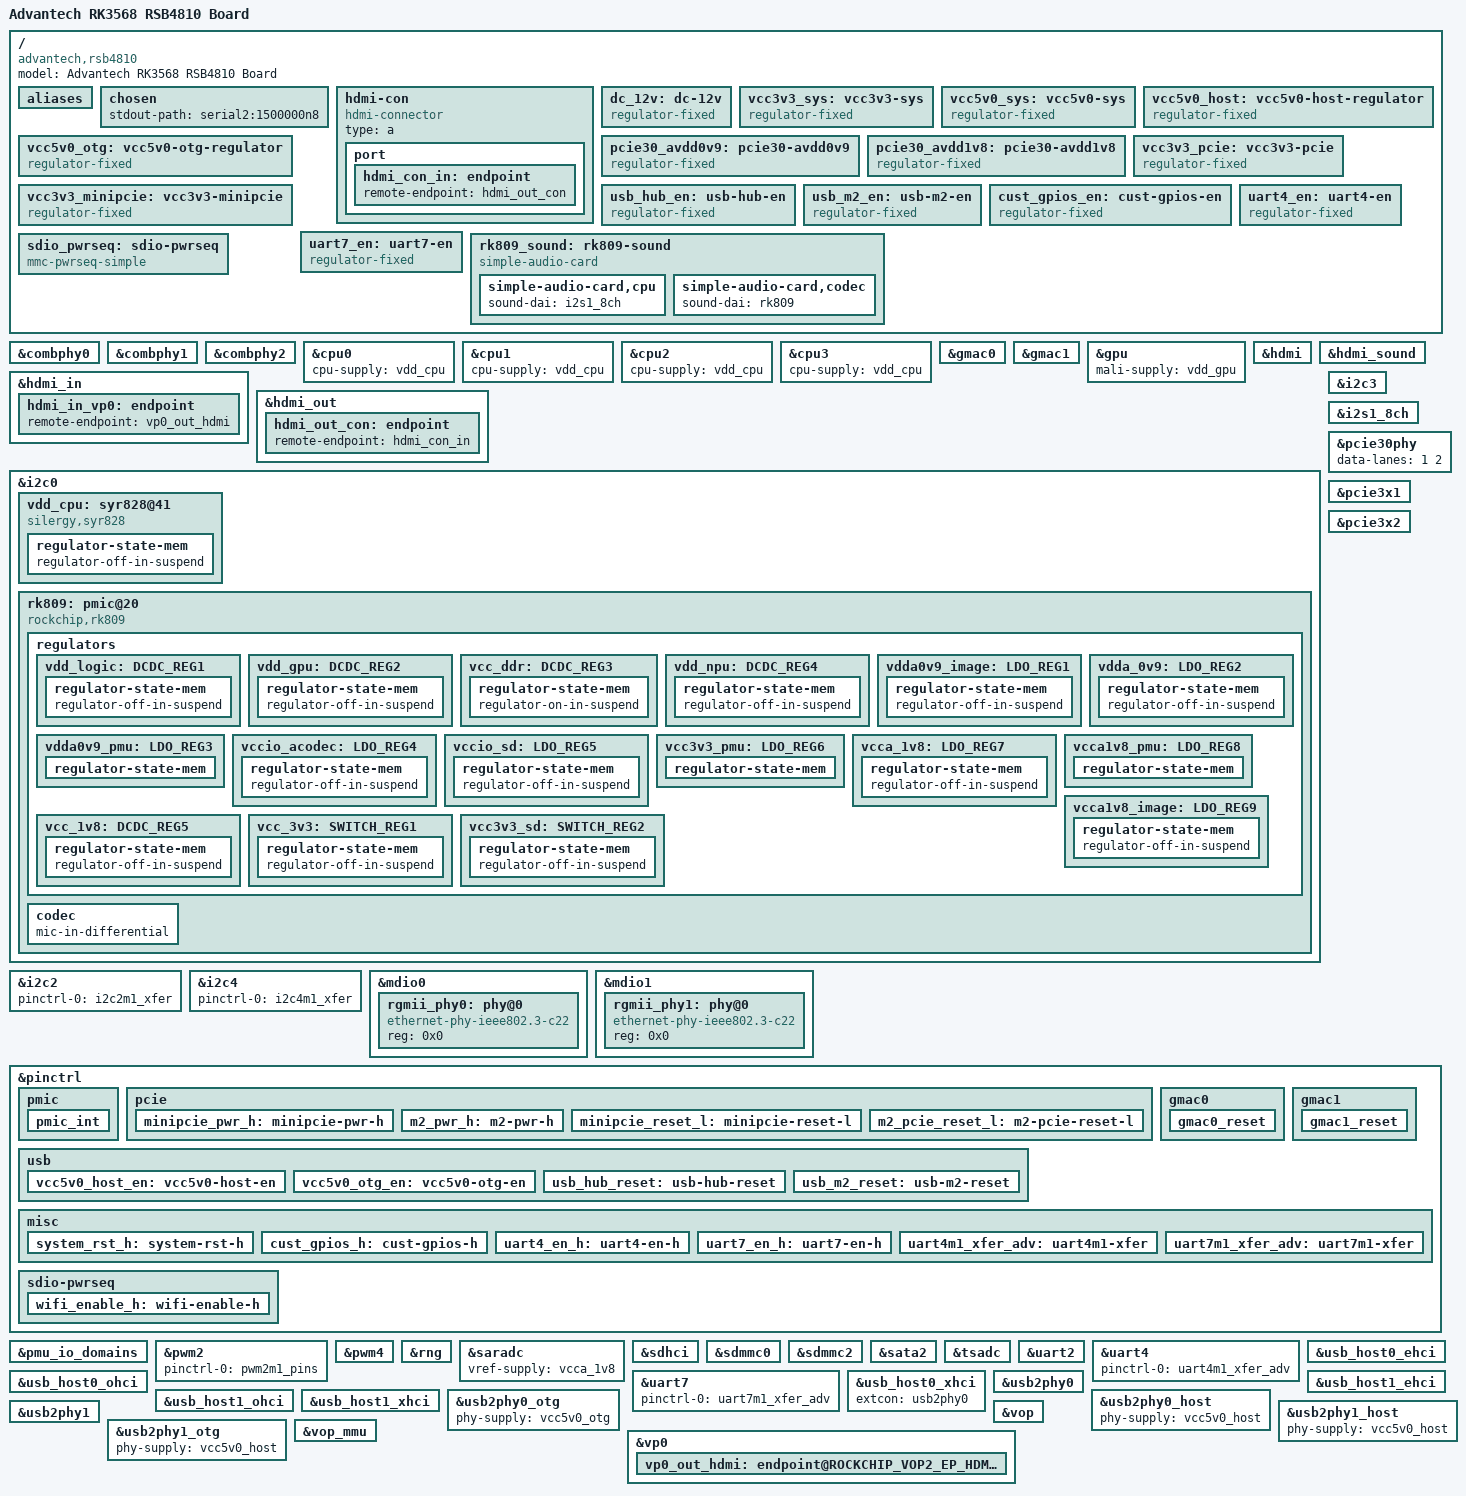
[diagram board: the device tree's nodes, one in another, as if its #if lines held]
// SPDX-License-Identifier: (GPL-2.0+ OR MIT)

/dts-v1/;
#include <dt-bindings/gpio/gpio.h>
#include <dt-bindings/pinctrl/rockchip.h>
#include <dt-bindings/soc/rockchip,vop2.h>
#include "rk3568.dtsi"

/ {
	model = "Advantech RK3568 RSB4810 Board";
	compatible = "advantech,rsb4810", "rockchip,rk3568";

	aliases {
		ethernet0 = &gmac0;
		ethernet1 = &gmac1;
		mmc0 = &sdhci;
		mmc1 = &sdmmc0;
	};

	chosen: chosen {
		stdout-path = "serial2:1500000n8";
	};

#ifdef DTS_NO_LEGACY
	hdmi-con {
		compatible = "hdmi-connector";
		type = "a";

		port {
			hdmi_con_in: endpoint {
				remote-endpoint = <&hdmi_out_con>;
			};
		};
	};
#endif

	dc_12v: dc-12v {
		compatible = "regulator-fixed";
		regulator-name = "dc_12v";
		regulator-always-on;
		regulator-boot-on;
		regulator-min-microvolt = <12000000>;
		regulator-max-microvolt = <12000000>;
	};

	vcc3v3_sys: vcc3v3-sys {
		compatible = "regulator-fixed";
		regulator-name = "vcc3v3_sys";
		regulator-always-on;
		regulator-boot-on;
		regulator-min-microvolt = <3300000>;
		regulator-max-microvolt = <3300000>;
		vin-supply = <&dc_12v>;
	};

	vcc5v0_sys: vcc5v0-sys {
		compatible = "regulator-fixed";
		regulator-name = "vcc5v0_sys";
		regulator-always-on;
		regulator-boot-on;
		regulator-min-microvolt = <5000000>;
		regulator-max-microvolt = <5000000>;
		vin-supply = <&dc_12v>;
	};

	vcc5v0_host: vcc5v0-host-regulator {
		compatible = "regulator-fixed";
		enable-active-high;
		gpio = <&gpio0 RK_PA6 GPIO_ACTIVE_HIGH>;
		pinctrl-names = "default";
		pinctrl-0 = <&vcc5v0_host_en>;
		regulator-name = "vcc5v0_host";
		regulator-min-microvolt = <5000000>;
		regulator-max-microvolt = <5000000>;
	};

	vcc5v0_otg: vcc5v0-otg-regulator {
		compatible = "regulator-fixed";
		enable-active-high;
		gpio = <&gpio0 RK_PA5 GPIO_ACTIVE_HIGH>;
		pinctrl-names = "default";
		pinctrl-0 = <&vcc5v0_otg_en>;
		regulator-name = "vcc5v0_otg";
		regulator-min-microvolt = <5000000>;
		regulator-max-microvolt = <5000000>;
	};

	pcie30_avdd0v9: pcie30-avdd0v9 {
		compatible = "regulator-fixed";
		regulator-name = "pcie30_avdd0v9";
		regulator-always-on;
		regulator-boot-on;
		regulator-min-microvolt = <900000>;
		regulator-max-microvolt = <900000>;
		vin-supply = <&vcc3v3_sys>;
	};

	pcie30_avdd1v8: pcie30-avdd1v8 {
		compatible = "regulator-fixed";
		regulator-name = "pcie30_avdd1v8";
		regulator-always-on;
		regulator-boot-on;
		regulator-min-microvolt = <1800000>;
		regulator-max-microvolt = <1800000>;
		vin-supply = <&vcc3v3_sys>;
	};

	vcc3v3_pcie: vcc3v3-pcie {
		compatible = "regulator-fixed";
		enable-active-high;
		gpios = <&gpio0 RK_PC6 GPIO_ACTIVE_HIGH>;
		pinctrl-0 = <&m2_pwr_h>;
		pinctrl-names = "default";
		regulator-name = "vcc3v3_pcie";
		regulator-min-microvolt = <3300000>;
		regulator-max-microvolt = <3300000>;
	};

	vcc3v3_minipcie: vcc3v3-minipcie {
		compatible = "regulator-fixed";
		enable-active-high;
		gpios = <&gpio0 RK_PD4 GPIO_ACTIVE_HIGH>;
		pinctrl-0 = <&minipcie_pwr_h>;
		pinctrl-names = "default";
		regulator-name = "vcc3v3_minipcie";
		regulator-min-microvolt = <3300000>;
		regulator-max-microvolt = <3300000>;
	};
	
	usb_hub_en: usb-hub-en {
		compatible = "regulator-fixed";
		enable-active-high;
		gpio = <&gpio0 RK_PB7 GPIO_ACTIVE_HIGH>;
		pinctrl-0 = <&usb_hub_reset>;
		pinctrl-names = "default";
		regulator-name = "usb_hub_en";
		regulator-always-on;
		regulator-boot-on;
	};

	usb_m2_en: usb-m2-en {
		compatible = "regulator-fixed";
		enable-active-high;
		gpio = <&gpio3 RK_PB5 GPIO_ACTIVE_HIGH>;
		pinctrl-0 = <&usb_m2_reset>;
		pinctrl-names = "default";
		regulator-name = "usb_m2_en";
		regulator-always-on;
		regulator-boot-on;
	};

	cust_gpios_en: cust-gpios-en {
		compatible = "regulator-fixed";
		enable-active-high;
		pinctrl-0 = <&cust_gpios_h>;
		pinctrl-names = "default";
		gpio = <&gpio2 RK_PD0 GPIO_ACTIVE_HIGH>;
		regulator-name = "cust_gpio_en";
		regulator-always-on;
		regulator-boot-on;
	};

	uart4_en: uart4-en {
		compatible = "regulator-fixed";
		enable-active-high;
		pinctrl-0 = <&uart4_en_h>;
		pinctrl-names = "default";
		gpio = <&gpio4 RK_PB2 GPIO_ACTIVE_HIGH>;
		regulator-name = "uart4_en";
		regulator-always-on;
		regulator-boot-on;
	};

	uart7_en: uart7-en {
		compatible = "regulator-fixed";
		enable-active-high;
		pinctrl-0 = <&uart7_en_h>;
		pinctrl-names = "default";
		gpio = <&gpio4 RK_PC0 GPIO_ACTIVE_HIGH>;
		regulator-name = "uart7_en";
		regulator-always-on;
		regulator-boot-on;
	};

	sdio_pwrseq: sdio-pwrseq {
		compatible = "mmc-pwrseq-simple";
		clocks = <&rk809 1>;
		clock-names = "ext_clock";
		pinctrl-0 = <&wifi_enable_h>;
		pinctrl-names = "default";

		/*
		 * On the module itself this is one of these (depending
		 * on the actual card populated):
		 * - SDIO_RESET_L_WL_REG_ON
		 * - PDN (power down when low)
		 */
		post-power-on-delay-ms = <200>;
		reset-gpios = <&gpio2 RK_PC6 GPIO_ACTIVE_LOW>;
	};

	rk809_sound: rk809-sound {
		compatible = "simple-audio-card";
		simple-audio-card,format = "i2s";
		simple-audio-card,name = "Analog RK809";
		simple-audio-card,mclk-fs = <256>;

		simple-audio-card,cpu {
			sound-dai = <&i2s1_8ch>;
		};
		simple-audio-card,codec {
			sound-dai = <&rk809>;
		};
	};
};

&combphy0 {
	status = "okay";
};

&combphy1 {
	status = "okay";
};

&combphy2 {
	status = "okay";
};

&cpu0 {
	cpu-supply = <&vdd_cpu>;
};

&cpu1 {
	cpu-supply = <&vdd_cpu>;
};

&cpu2 {
	cpu-supply = <&vdd_cpu>;
};

&cpu3 {
	cpu-supply = <&vdd_cpu>;
};

&gmac0 {
	assigned-clocks = <&cru SCLK_GMAC0_RX_TX>, <&cru SCLK_GMAC0>;
	assigned-clock-parents = <&cru SCLK_GMAC0_RGMII_SPEED>, <&cru CLK_MAC0_2TOP>;
	assigned-clock-rates = <0>, <125000000>;
	clock_in_out = "input";
	phy-mode = "rgmii";
	pinctrl-names = "default";
	pinctrl-0 = <&gmac0_reset
		     &gmac0_miim
		     &gmac0_tx_bus2
		     &gmac0_rx_bus2
		     &gmac0_rgmii_clk
		     &gmac0_rgmii_bus>;
	snps,reset-gpio = <&gpio3 RK_PB7 GPIO_ACTIVE_LOW>;
	snps,reset-active-low;
	/* Reset time is 20ms, 100ms for rtl8211f */
	snps,reset-delays-us = <0 20000 100000>;
	enable_phy_delay = <0>;
	tx_delay = <0x37>;
	rx_delay = <0x0d>;
	phy-handle = <&rgmii_phy0>;
	status = "okay";
};

&gmac1 {
	assigned-clocks = <&cru SCLK_GMAC1_RX_TX>, <&cru SCLK_GMAC1>;
	assigned-clock-parents = <&cru SCLK_GMAC1_RGMII_SPEED>, <&cru CLK_MAC1_2TOP>;
	assigned-clock-rates = <0>, <125000000>;
	clock_in_out = "input";
	phy-mode = "rgmii";
	pinctrl-names = "default";
	pinctrl-0 = <&gmac1_reset
		     &gmac1m1_miim
		     &gmac1m1_tx_bus2
		     &gmac1m1_rx_bus2
		     &gmac1m1_rgmii_clk
		     &gmac1m1_rgmii_bus
		     &gmac1m1_clkinout>;
	snps,reset-gpio = <&gpio3 RK_PB0 GPIO_ACTIVE_LOW>;
	snps,reset-active-low;
	/* Reset time is 20ms, 100ms for rtl8211f */
	snps,reset-delays-us = <0 20000 100000>;
	enable_phy_delay = <0>;
	tx_delay = <0x3c>;
	rx_delay = <0x2f>;
	phy-handle = <&rgmii_phy1>;
	status = "okay";
};

#ifdef DTS_NO_LEGACY
&gpu {
	mali-supply = <&vdd_gpu>;
	status = "okay";
};

&hdmi {
	status = "okay";
};

&hdmi_in {
	hdmi_in_vp0: endpoint {
		remote-endpoint = <&vp0_out_hdmi>;
	};
};

&hdmi_out {
	hdmi_out_con: endpoint {
		remote-endpoint = <&hdmi_con_in>;
	};
};

&hdmi_sound {
	status = "okay";
};
#endif

&i2c0 {
	status = "okay";

	vdd_cpu: syr828@41 {
		compatible = "silergy,syr828";
		reg = <0x41>;
		vin-supply = <&vcc5v0_sys>;
		regulator-compatible = "fan53555-reg";
		regulator-name = "vdd_cpu";
		regulator-min-microvolt = <800000>;
		regulator-max-microvolt = <1250000>;
		regulator-ramp-delay = <1000>;
		fcs,suspend-voltage-selector = <1>;
		regulator-always-on;
		regulator-boot-on;

		regulator-state-mem {
			regulator-off-in-suspend;
		};
	};

	rk809: pmic@20 {
		compatible = "rockchip,rk809";
		reg = <0x20>;
		interrupt-parent = <&gpio0>;
		interrupts = <RK_PA3 IRQ_TYPE_LEVEL_LOW>;
		assigned-clocks = <&cru I2S1_MCLKOUT_TX>;
		assigned-clock-parents = <&cru CLK_I2S1_8CH_TX>;
		#clock-cells = <1>;
		clock-names = "mclk";
		clocks = <&cru I2S1_MCLKOUT_TX>;
		pinctrl-names = "default";
		pinctrl-0 = <&pmic_int>, <&i2s1m0_mclk>;
		rockchip,system-power-controller;
		#sound-dai-cells = <0>;
		wakeup-source;

		vcc1-supply = <&vcc3v3_sys>;
		vcc2-supply = <&vcc3v3_sys>;
		vcc3-supply = <&vcc3v3_sys>;
		vcc4-supply = <&vcc3v3_sys>;
		vcc5-supply = <&vcc3v3_sys>;
		vcc6-supply = <&vcc3v3_sys>;
		vcc7-supply = <&vcc3v3_sys>;
		vcc8-supply = <&vcc3v3_sys>;
		vcc9-supply = <&vcc3v3_sys>;

		regulators {
			vdd_logic: DCDC_REG1 {
				regulator-always-on;
				regulator-boot-on;
				regulator-min-microvolt = <500000>;
				regulator-max-microvolt = <1350000>;
				regulator-init-microvolt = <900000>;
				regulator-ramp-delay = <6001>;
				regulator-initial-mode = <0x2>;
				regulator-name = "vdd_logic";

				regulator-state-mem {
					regulator-off-in-suspend;
				};
			};

			vdd_gpu: DCDC_REG2 {
				regulator-always-on;
				regulator-boot-on;
				regulator-min-microvolt = <500000>;
				regulator-max-microvolt = <1350000>;
				regulator-init-microvolt = <900000>;
				regulator-ramp-delay = <6001>;
				regulator-initial-mode = <0x2>;
				regulator-name = "vdd_gpu";

				regulator-state-mem {
					regulator-off-in-suspend;
				};
			};

			vcc_ddr: DCDC_REG3 {
				regulator-always-on;
				regulator-boot-on;
				regulator-initial-mode = <0x2>;
				regulator-name = "vcc_ddr";

				regulator-state-mem {
					regulator-on-in-suspend;
				};
			};

			vdd_npu: DCDC_REG4 {
				regulator-always-on;
				regulator-boot-on;
				regulator-min-microvolt = <500000>;
				regulator-max-microvolt = <1350000>;
				regulator-init-microvolt = <900000>;
				regulator-ramp-delay = <6001>;
				regulator-initial-mode = <0x2>;
				regulator-name = "vdd_npu";

				regulator-state-mem {
					regulator-off-in-suspend;
				};
			};

			vdda0v9_image: LDO_REG1 {
				regulator-boot-on;
				regulator-always-on;
				regulator-min-microvolt = <900000>;
				regulator-max-microvolt = <900000>;
				regulator-name = "vdda0v9_image";

				regulator-state-mem {
					regulator-off-in-suspend;
				};
			};

			vdda_0v9: LDO_REG2 {
				regulator-always-on;
				regulator-boot-on;
				regulator-min-microvolt = <900000>;
				regulator-max-microvolt = <900000>;
				regulator-name = "vdda_0v9";

				regulator-state-mem {
					regulator-off-in-suspend;
				};
			};

			vdda0v9_pmu: LDO_REG3 {
				regulator-always-on;
				regulator-boot-on;
				regulator-min-microvolt = <900000>;
				regulator-max-microvolt = <900000>;
				regulator-name = "vdda0v9_pmu";

				regulator-state-mem {
					regulator-on-in-suspend;
					regulator-suspend-microvolt = <900000>;
				};
			};

			vccio_acodec: LDO_REG4 {
				regulator-always-on;
				regulator-boot-on;
				regulator-min-microvolt = <3300000>;
				regulator-max-microvolt = <3300000>;
				regulator-name = "vccio_acodec";

				regulator-state-mem {
					regulator-off-in-suspend;
				};
			};

			vccio_sd: LDO_REG5 {
				regulator-always-on;
				regulator-boot-on;
				regulator-min-microvolt = <1800000>;
				regulator-max-microvolt = <3300000>;
				regulator-name = "vccio_sd";
				regulator-state-mem {
					regulator-off-in-suspend;
				};
			};

			vcc3v3_pmu: LDO_REG6 {
				regulator-always-on;
				regulator-boot-on;
				regulator-min-microvolt = <3300000>;
				regulator-max-microvolt = <3300000>;
				regulator-name = "vcc3v3_pmu";

				regulator-state-mem {
					regulator-on-in-suspend;
					regulator-suspend-microvolt = <3300000>;
				};
			};

			vcca_1v8: LDO_REG7 {
				regulator-always-on;
				regulator-boot-on;
				regulator-min-microvolt = <1800000>;
				regulator-max-microvolt = <1800000>;
				regulator-name = "vcca_1v8";

				regulator-state-mem {
					regulator-off-in-suspend;
				};
			};

			vcca1v8_pmu: LDO_REG8 {
				regulator-always-on;
				regulator-boot-on;
				regulator-min-microvolt = <1800000>;
				regulator-max-microvolt = <1800000>;
				regulator-name = "vcca1v8_pmu";

				regulator-state-mem {
					regulator-on-in-suspend;
					regulator-suspend-microvolt = <1800000>;
				};
			};

			vcca1v8_image: LDO_REG9 {
				regulator-always-on;
				regulator-boot-on;
				regulator-min-microvolt = <1800000>;
				regulator-max-microvolt = <1800000>;
				regulator-name = "vcca1v8_image";

				regulator-state-mem {
					regulator-off-in-suspend;
				};
			};

			vcc_1v8: DCDC_REG5 {
				regulator-always-on;
				regulator-boot-on;
				regulator-min-microvolt = <1800000>;
				regulator-max-microvolt = <1800000>;
				regulator-name = "vcc_1v8";

				regulator-state-mem {
					regulator-off-in-suspend;
				};
			};

			vcc_3v3: SWITCH_REG1 {
				regulator-always-on;
				regulator-boot-on;
				regulator-name = "vcc_3v3";

				regulator-state-mem {
					regulator-off-in-suspend;
				};
			};

			vcc3v3_sd: SWITCH_REG2 {
				regulator-always-on;
				regulator-boot-on;
				regulator-name = "vcc3v3_sd";

				regulator-state-mem {
					regulator-off-in-suspend;
				};
			};
		};

		codec {
			mic-in-differential;
		};
	};
};

&i2c2 {
	status = "okay";
	pinctrl-names = "default";
	pinctrl-0 = <&i2c2m1_xfer>;
};

&i2c3 {
	status = "okay";
};

&i2c4 {
	status = "okay";
	pinctrl-names = "default";
	pinctrl-0 = <&i2c4m1_xfer>;
};

&i2s1_8ch {
	status = "okay";
	rockchip,trcm-sync-tx-only;
	pinctrl-names = "default";
	pinctrl-0 = <&i2s1m0_sclktx
		     &i2s1m0_lrcktx
		     &i2s1m0_sdi0
		     &i2s1m0_sdo0>;
};

&mdio0 {
	rgmii_phy0: phy@0 {
		compatible = "ethernet-phy-ieee802.3-c22";
		reg = <0x0>;
	};
};

&mdio1 {
	rgmii_phy1: phy@0 {
		compatible = "ethernet-phy-ieee802.3-c22";
		reg = <0x0>;
	};
};

&pcie30phy {
	data-lanes = <1 2>;
	status = "okay";
};

&pcie3x1 {
	num-lanes = <1>;
	pinctrl-names = "default";
	pinctrl-0 = <&minipcie_reset_l>;
	reset-gpios = <&gpio2 RK_PD6 GPIO_ACTIVE_HIGH>;
	vpcie3v3-supply = <&vcc3v3_minipcie>;
	status = "okay";
};

&pcie3x2 {
	num-lanes = <1>;
	pinctrl-names = "default";
	pinctrl-0 = <&m2_pcie_reset_l>;
	reset-gpios = <&gpio3 RK_PA1 GPIO_ACTIVE_HIGH>;
	vpcie3v3-supply = <&vcc3v3_pcie>;
	status = "okay";
};

&pinctrl {
	pmic {
		pmic_int: pmic_int {
			rockchip,pins = <0 RK_PA3 RK_FUNC_GPIO &pcfg_pull_up>;
		};
	};

	pcie {
		minipcie_pwr_h: minipcie-pwr-h {
			rockchip,pins = <0 RK_PD4 RK_FUNC_GPIO &pcfg_pull_up>;
		};

		m2_pwr_h: m2-pwr-h {
			rockchip,pins = <0 RK_PC6 RK_FUNC_GPIO &pcfg_pull_none>; 
		};

		minipcie_reset_l: minipcie-reset-l {
			rockchip,pins = <2 RK_PD6 RK_FUNC_GPIO &pcfg_pull_none>;
		};

		m2_pcie_reset_l: m2-pcie-reset-l {
			rockchip,pins = <3 RK_PA1 RK_FUNC_GPIO &pcfg_pull_down>;
		};
	};

	usb {
		vcc5v0_host_en: vcc5v0-host-en {
			rockchip,pins = <0 RK_PA6 RK_FUNC_GPIO &pcfg_pull_none>;
		};

		vcc5v0_otg_en: vcc5v0-otg-en {
			rockchip,pins = <0 RK_PA5 RK_FUNC_GPIO &pcfg_pull_none>;
		};

		usb_hub_reset: usb-hub-reset {
			rockchip,pins = <0 RK_PB7 RK_FUNC_GPIO &pcfg_pull_up>;
		};

		usb_m2_reset: usb-m2-reset {
			rockchip,pins = <3 RK_PB5 RK_FUNC_GPIO &pcfg_pull_up>;
		};
	};
	
	gmac0 {
		gmac0_reset: gmac0_reset {
			rockchip,pins = <3 RK_PB7 RK_FUNC_GPIO &pcfg_pull_down>;
		};
	};

	gmac1 {
		gmac1_reset: gmac1_reset {
			rockchip,pins = <3 RK_PB0 RK_FUNC_GPIO &pcfg_pull_down>;
		};
	};

	misc {
		system_rst_h: system-rst-h {
			rockchip,pins = <0 RK_PA1 RK_FUNC_GPIO &pcfg_pull_down>;
		};

		cust_gpios_h: cust-gpios-h {
			rockchip,pins = <3 RK_PA0 RK_FUNC_GPIO &pcfg_pull_none>,
				<3 RK_PA2 RK_FUNC_GPIO &pcfg_pull_none>,
				<3 RK_PA3 RK_FUNC_GPIO &pcfg_pull_none>,
				<3 RK_PA4 RK_FUNC_GPIO &pcfg_pull_none>,
				<3 RK_PA5 RK_FUNC_GPIO &pcfg_pull_none>,
				<3 RK_PA6 RK_FUNC_GPIO &pcfg_pull_none>;
		};

		uart4_en_h: uart4-en-h {
			rockchip,pins = <4 RK_PB2 RK_FUNC_GPIO &pcfg_pull_up>;
		};

		uart7_en_h: uart7-en-h {
			rockchip,pins = <4 RK_PC0 RK_FUNC_GPIO &pcfg_pull_up>;
		};

		uart4m1_xfer_adv: uart4m1-xfer {
			rockchip,pins = <3 RK_PB1 4 &pcfg_pull_down>,
				<3 RK_PB2 4 &pcfg_pull_down>;
		};

		uart7m1_xfer_adv: uart7m1-xfer {
			rockchip,pins = <3 RK_PC5 4 &pcfg_pull_down>,
				<3 RK_PC4 4 &pcfg_pull_down>;
		};
	};

	sdio-pwrseq {
		wifi_enable_h: wifi-enable-h {
			rockchip,pins = <2 RK_PC6 RK_FUNC_GPIO &pcfg_pull_none>;
		};
	};
};

&pmu_io_domains {
	status = "okay";
	pmuio1-supply = <&vcc3v3_pmu>;
	pmuio2-supply = <&vcc3v3_pmu>;
	vccio1-supply = <&vccio_acodec>;
	vccio3-supply = <&vccio_sd>;
	vccio4-supply = <&vcc_1v8>;
	vccio5-supply = <&vcc_3v3>;
	vccio6-supply = <&vcc_1v8>;
	vccio7-supply = <&vcc_3v3>;
};

&pwm2 {
	status = "okay";
	pinctrl-names = "active";
	pinctrl-0 = <&pwm2m1_pins>;
};

&pwm4 {
	status = "okay";
};

&rng {
	status = "okay";
};

&saradc {
	vref-supply = <&vcca_1v8>;
	status = "okay";
};

&sdhci {
	bus-width = <8>;
	non-removable;
	max-frequency = <200000000>;
	status = "okay";
};

&sdmmc0 {
	broken-cd;
	bus-width = <4>;
	cap-sd-highspeed;
	disable-wp;
	sd-uhs-sdr104;
	vmmc-supply = <&vcc3v3_sd>;
	vqmmc-supply = <&vccio_sd>;
	pinctrl-names = "default";
	pinctrl-0 = <&sdmmc0_bus4 &sdmmc0_clk &sdmmc0_cmd &sdmmc0_det>;
	status = "okay";
};

&sdmmc2 {
	bus-width = <4>;
	cap-sd-highspeed;
	cap-sdio-irq;
	disable-wp;
	keep-power-in-suspend;
	mmc-pwrseq = <&sdio_pwrseq>;
	non-removable;
	pinctrl-names = "default";
	pinctrl-0 = <&sdmmc2m0_bus4 &sdmmc2m0_cmd &sdmmc2m0_clk>;
	status = "okay";
};

&sata2 {
	status = "okay";
};

&tsadc {
	status = "okay";
};

&uart2 {
	status = "okay";
};

&uart4 {
	pinctrl-0 = <&uart4m1_xfer_adv>;
	pinctrl-names = "default";
	status = "okay";
};

&uart7 {
	pinctrl-0 = <&uart7m1_xfer_adv>;
	pinctrl-names = "default";
	status = "okay";
};

&usb_host0_ehci {
	status = "okay";
};

&usb_host0_ohci {
	status = "okay";
};

&usb_host0_xhci {
	extcon = <&usb2phy0>;
	status = "okay";
};

&usb_host1_ehci {
	status = "okay";
};

&usb_host1_ohci {
	status = "okay";
};

&usb_host1_xhci {
	status = "okay";
};

&usb2phy0 {
	status = "okay";
};

&usb2phy0_host {
	phy-supply = <&vcc5v0_host>;
	status = "okay";
};

&usb2phy0_otg {
	phy-supply = <&vcc5v0_otg>;
	status = "okay";
};

&usb2phy1 {
	status = "okay";
};

&usb2phy1_host {
	phy-supply = <&vcc5v0_host>;
	status = "okay";
};

&usb2phy1_otg {
	phy-supply = <&vcc5v0_host>;
	status = "okay";
};

#ifdef DTS_NO_LEGACY
&vop {
	assigned-clocks = <&cru DCLK_VOP0>, <&cru DCLK_VOP1>;
	assigned-clock-parents = <&pmucru PLL_HPLL>, <&cru PLL_VPLL>;
	status = "okay";
};

&vop_mmu {
	status = "okay";
};

&vp0 {
	vp0_out_hdmi: endpoint@ROCKCHIP_VOP2_EP_HDMI0 {
		reg = <ROCKCHIP_VOP2_EP_HDMI0>;
		remote-endpoint = <&hdmi_in_vp0>;
	};
};
#endif
